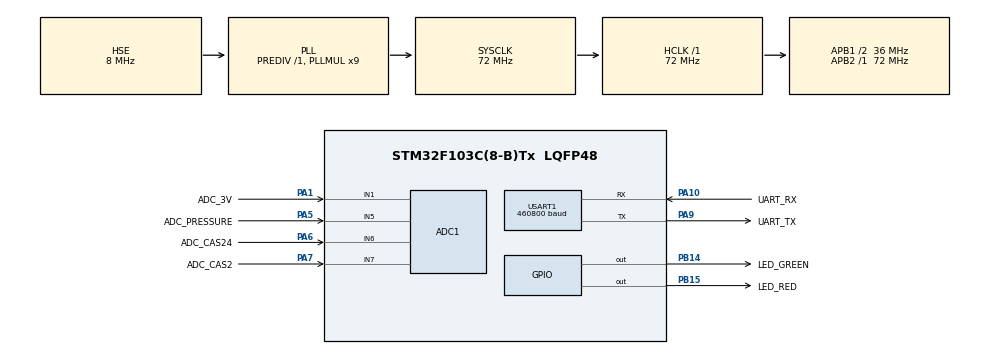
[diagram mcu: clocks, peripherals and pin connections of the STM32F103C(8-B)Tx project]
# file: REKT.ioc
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ADC1.Channel-10\#ChannelRegularConversion=ADC_CHANNEL_7
ADC1.Channel-8\#ChannelRegularConversion=ADC_CHANNEL_5
ADC1.Channel-9\#ChannelRegularConversion=ADC_CHANNEL_6
ADC1.ContinuousConvMode=ENABLE
ADC1.DataAlign=ADC_DATAALIGN_RIGHT
ADC1.DiscontinuousConvMode=DISABLE
ADC1.EnableAnalogWatchDog=false
ADC1.EnableRegularConversion=ENABLE
ADC1.ExternalTrigConv=ADC_SOFTWARE_START
ADC1.InjNumberOfConversion=0
ADC1.NbrOfConversion=3
ADC1.NbrOfConversionFlag=1
ADC1.Rank-10\#ChannelRegularConversion=3
ADC1.Rank-8\#ChannelRegularConversion=1
ADC1.Rank-9\#ChannelRegularConversion=2
ADC1.SamplingTime-10\#ChannelRegularConversion=ADC_SAMPLETIME_13CYCLES_5
ADC1.SamplingTime-8\#ChannelRegularConversion=ADC_SAMPLETIME_13CYCLES_5
ADC1.SamplingTime-9\#ChannelRegularConversion=ADC_SAMPLETIME_13CYCLES_5
ADC1.ScanConvMode=ADC_SCAN_ENABLE
ADC1.master=1
Dma.ADC1.0.Direction=DMA_PERIPH_TO_MEMORY
Dma.ADC1.0.Instance=DMA1_Channel1
Dma.ADC1.0.MemDataAlignment=DMA_MDATAALIGN_WORD
Dma.ADC1.0.MemInc=DMA_MINC_ENABLE
Dma.ADC1.0.Mode=DMA_CIRCULAR
Dma.ADC1.0.PeriphDataAlignment=DMA_PDATAALIGN_WORD
Dma.ADC1.0.PeriphInc=DMA_PINC_DISABLE
Dma.ADC1.0.Priority=DMA_PRIORITY_LOW
Dma.Request0=ADC1
Mcu.Family=STM32F1
Mcu.Name=STM32F103C(8-B)Tx
Mcu.Package=LQFP48
NVIC.DMA1_Channel1_IRQn=true\:0\:0\:true\:true\:true\:1\:false
NVIC.PriorityGroup=NVIC_PRIORITYGROUP_4
NVIC.TIM1_UP_IRQn=true\:0\:0\:false\:false\:true\:true
PA1.GPIO_Label=ADC_3V
PA1.Signal=ADCx_IN1
PA10.GPIO_Label=UART_RX
PA10.Mode=Asynchronous
PA10.Signal=USART1_RX
PA13.Mode=Serial_Wire
PA13.Signal=SYS_JTMS-SWDIO
PA14.Mode=Serial_Wire
PA14.Signal=SYS_JTCK-SWCLK
PA5.GPIO_Label=ADC_PRESSURE
PA5.Signal=ADCx_IN5
PA6.GPIO_Label=ADC_CAS24
PA6.Signal=ADCx_IN6
PA7.GPIO_Label=ADC_CAS2
PA7.Signal=ADCx_IN7
PA9.GPIO_Label=UART_TX
PA9.Mode=Asynchronous
PA9.Signal=USART1_TX
PB14.GPIO_Label=LED_GREEN
PB14.Signal=GPIO_Output
PB15.GPIO_Label=LED_RED
PB15.Signal=GPIO_Output
PD0-OSC_IN.Mode=HSE-External-Oscillator
PD0-OSC_IN.Signal=RCC_OSC_IN
PD1-OSC_OUT.Mode=HSE-External-Oscillator
PD1-OSC_OUT.Signal=RCC_OSC_OUT
ProjectManager.HeapSize=0x200
ProjectManager.StackSize=0x400
ProjectManager.TargetToolchain=Other Toolchains (GPDSC)
RCC.ADCPresc=RCC_ADCPCLK2_DIV6
RCC.AHBFreq_Value=72000000
RCC.APB1CLKDivider=RCC_HCLK_DIV2
RCC.APB1Freq_Value=36000000
RCC.APB1TimFreq_Value=72000000
RCC.APB2Freq_Value=72000000
RCC.APB2TimFreq_Value=72000000
RCC.HCLKFreq_Value=72000000
RCC.PLLMUL=RCC_PLL_MUL9
RCC.PLLSourceVirtual=RCC_PLLSOURCE_HSE
RCC.SYSCLKFreq_VALUE=72000000
RCC.SYSCLKSource=RCC_SYSCLKSOURCE_PLLCLK
RCC.USBFreq_Value=72000000
SH.ADCx_IN1.0=ADC1_IN1,IN1
SH.ADCx_IN5.0=ADC1_IN5,IN5
SH.ADCx_IN6.0=ADC1_IN6,IN6
SH.ADCx_IN7.0=ADC1_IN7,IN7
TIM1.Period=99
TIM1.Prescaler=71
USART1.BaudRate=460800
USART1.Mode=MODE_TX
USART1.VirtualMode=VM_ASYNC
VP_ADC1_Vref_Input.Mode=IN-Vrefint
VP_TIM1_VS_ClockSourceINT.Mode=Internal
board=REKT

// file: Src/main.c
/**
  ******************************************************************************
  * @file           : main.c
  * @brief          : Main program body
  ******************************************************************************
  ** This notice applies to any and all portions of this file
  * that are not between comment pairs USER CODE BEGIN and
  * USER CODE END. Other portions of this file, whether
  * inserted by the user or by software development tools
  * are owned by their respective copyright owners.
  *
  * COPYRIGHT(c) 2018 STMicroelectronics
  *
  * Redistribution and use in source and binary forms, with or without modification,
  * are permitted provided that the following conditions are met:
  *   1. Redistributions of source code must retain the above copyright notice,
  *      this list of conditions and the following disclaimer.
  *   2. Redistributions in binary form must reproduce the above copyright notice,
  *      this list of conditions and the following disclaimer in the documentation
  *      and/or other materials provided with the distribution.
  *   3. Neither the name of STMicroelectronics nor the names of its contributors
  *      may be used to endorse or promote products derived from this software
  *      without specific prior written permission.
  *
  * THIS SOFTWARE IS PROVIDED BY THE COPYRIGHT HOLDERS AND CONTRIBUTORS "AS IS"
  * AND ANY EXPRESS OR IMPLIED WARRANTIES, INCLUDING, BUT NOT LIMITED TO, THE
  * IMPLIED WARRANTIES OF MERCHANTABILITY AND FITNESS FOR A PARTICULAR PURPOSE ARE
  * DISCLAIMED. IN NO EVENT SHALL THE COPYRIGHT HOLDER OR CONTRIBUTORS BE LIABLE
  * FOR ANY DIRECT, INDIRECT, INCIDENTAL, SPECIAL, EXEMPLARY, OR CONSEQUENTIAL
  * DAMAGES (INCLUDING, BUT NOT LIMITED TO, PROCUREMENT OF SUBSTITUTE GOODS OR
  * SERVICES; LOSS OF USE, DATA, OR PROFITS; OR BUSINESS INTERRUPTION) HOWEVER
  * CAUSED AND ON ANY THEORY OF LIABILITY, WHETHER IN CONTRACT, STRICT LIABILITY,
  * OR TORT (INCLUDING NEGLIGENCE OR OTHERWISE) ARISING IN ANY WAY OUT OF THE USE
  * OF THIS SOFTWARE, EVEN IF ADVISED OF THE POSSIBILITY OF SUCH DAMAGE.
  *
  ******************************************************************************
  */
#include "main.h"
#include "stm32f1xx_hal.h"

/* USER CODE BEGIN Includes */
#include "rekt.h"
/* USER CODE END Includes */

ADC_HandleTypeDef hadc1;
DMA_HandleTypeDef hdma_adc1;

TIM_HandleTypeDef htim1;

UART_HandleTypeDef huart1;

void SystemClock_Config(void);
static void MX_GPIO_Init(void);
static void MX_DMA_Init(void);
static void MX_USART1_UART_Init(void);
static void MX_ADC1_Init(void);
static void MX_TIM1_Init(void);
static void MX_NVIC_Init(void);

int main(void)
{
  /* USER CODE BEGIN 1 */
#if DEBUG
  HAL_DBGMCU_EnableDBGSleepMode();
  HAL_DBGMCU_EnableDBGStopMode();
  HAL_DBGMCU_EnableDBGStandbyMode();
#endif
  /* USER CODE END 1 */

  /* MCU Configuration----------------------------------------------------------*/

  /* Reset of all peripherals, Initializes the Flash interface and the Systick. */
  HAL_Init();

  /* Configure the system clock */
  SystemClock_Config();

  /* Initialize all configured peripherals */
  MX_GPIO_Init();
  MX_DMA_Init();
  MX_USART1_UART_Init();
  MX_ADC1_Init();
  MX_TIM1_Init();

  /* Initialize interrupts */
  MX_NVIC_Init();
  /* USER CODE BEGIN 2 */
  rekt_init();
  rekt_loop();
  /* USER CODE END 2 */

  /* Infinite loop */
  while (1)
  {

  }

}

void SystemClock_Config(void)
{

  RCC_OscInitTypeDef RCC_OscInitStruct;
  RCC_ClkInitTypeDef RCC_ClkInitStruct;
  RCC_PeriphCLKInitTypeDef PeriphClkInit;

    /**Initializes the CPU, AHB and APB busses clocks
    */
  RCC_OscInitStruct.OscillatorType = RCC_OSCILLATORTYPE_HSE;
  RCC_OscInitStruct.HSEState = RCC_HSE_ON;
  RCC_OscInitStruct.HSEPredivValue = RCC_HSE_PREDIV_DIV1;
  RCC_OscInitStruct.HSIState = RCC_HSI_ON;
  RCC_OscInitStruct.PLL.PLLState = RCC_PLL_ON;
  RCC_OscInitStruct.PLL.PLLSource = RCC_PLLSOURCE_HSE;
  RCC_OscInitStruct.PLL.PLLMUL = RCC_PLL_MUL9;
  if (HAL_RCC_OscConfig(&RCC_OscInitStruct) != HAL_OK)
  {
    _Error_Handler(__FILE__, __LINE__);
  }

    /**Initializes the CPU, AHB and APB busses clocks
    */
  RCC_ClkInitStruct.ClockType = RCC_CLOCKTYPE_HCLK|RCC_CLOCKTYPE_SYSCLK
                              |RCC_CLOCKTYPE_PCLK1|RCC_CLOCKTYPE_PCLK2;
  RCC_ClkInitStruct.SYSCLKSource = RCC_SYSCLKSOURCE_PLLCLK;
  RCC_ClkInitStruct.AHBCLKDivider = RCC_SYSCLK_DIV1;
  RCC_ClkInitStruct.APB1CLKDivider = RCC_HCLK_DIV2;
  RCC_ClkInitStruct.APB2CLKDivider = RCC_HCLK_DIV1;

  if (HAL_RCC_ClockConfig(&RCC_ClkInitStruct, FLASH_LATENCY_2) != HAL_OK)
  {
    _Error_Handler(__FILE__, __LINE__);
  }

  PeriphClkInit.PeriphClockSelection = RCC_PERIPHCLK_ADC;
  PeriphClkInit.AdcClockSelection = RCC_ADCPCLK2_DIV6;
  if (HAL_RCCEx_PeriphCLKConfig(&PeriphClkInit) != HAL_OK)
  {
    _Error_Handler(__FILE__, __LINE__);
  }

    /**Configure the Systick interrupt time
    */
  HAL_SYSTICK_Config(HAL_RCC_GetHCLKFreq()/1000);

    /**Configure the Systick
    */
  HAL_SYSTICK_CLKSourceConfig(SYSTICK_CLKSOURCE_HCLK);

  /* SysTick_IRQn interrupt configuration */
  HAL_NVIC_SetPriority(SysTick_IRQn, 0, 0);
}

/**
  * @brief NVIC Configuration.
  * @retval None
  */
static void MX_NVIC_Init(void)
{
  /* DMA1_Channel1_IRQn interrupt configuration */
  HAL_NVIC_SetPriority(DMA1_Channel1_IRQn, 0, 0);
  HAL_NVIC_EnableIRQ(DMA1_Channel1_IRQn);
}

/* ADC1 init function */
static void MX_ADC1_Init(void)
{

  ADC_ChannelConfTypeDef sConfig;

    /**Common config
    */
  hadc1.Instance = ADC1;
  hadc1.Init.ScanConvMode = ADC_SCAN_ENABLE;
  hadc1.Init.ContinuousConvMode = ENABLE;
  hadc1.Init.DiscontinuousConvMode = DISABLE;
  hadc1.Init.ExternalTrigConv = ADC_SOFTWARE_START;
  hadc1.Init.DataAlign = ADC_DATAALIGN_RIGHT;
  hadc1.Init.NbrOfConversion = 3;
  if (HAL_ADC_Init(&hadc1) != HAL_OK)
  {
    _Error_Handler(__FILE__, __LINE__);
  }

    /**Configure Regular Channel
    */
  sConfig.Channel = ADC_CHANNEL_5;
  sConfig.Rank = ADC_REGULAR_RANK_1;
  sConfig.SamplingTime = ADC_SAMPLETIME_13CYCLES_5;
  if (HAL_ADC_ConfigChannel(&hadc1, &sConfig) != HAL_OK)
  {
    _Error_Handler(__FILE__, __LINE__);
  }

    /**Configure Regular Channel
    */
  sConfig.Channel = ADC_CHANNEL_6;
  sConfig.Rank = ADC_REGULAR_RANK_2;
  if (HAL_ADC_ConfigChannel(&hadc1, &sConfig) != HAL_OK)
  {
    _Error_Handler(__FILE__, __LINE__);
  }

    /**Configure Regular Channel
    */
  sConfig.Channel = ADC_CHANNEL_7;
  sConfig.Rank = ADC_REGULAR_RANK_3;
  if (HAL_ADC_ConfigChannel(&hadc1, &sConfig) != HAL_OK)
  {
    _Error_Handler(__FILE__, __LINE__);
  }

}

/* TIM1 init function */
static void MX_TIM1_Init(void)
{

  TIM_ClockConfigTypeDef sClockSourceConfig;
  TIM_MasterConfigTypeDef sMasterConfig;

  htim1.Instance = TIM1;
  htim1.Init.Prescaler = 71;
  htim1.Init.CounterMode = TIM_COUNTERMODE_UP;
  htim1.Init.Period = 99;
  htim1.Init.ClockDivision = TIM_CLOCKDIVISION_DIV1;
  htim1.Init.RepetitionCounter = 0;
  htim1.Init.AutoReloadPreload = TIM_AUTORELOAD_PRELOAD_DISABLE;
  if (HAL_TIM_Base_Init(&htim1) != HAL_OK)
  {
    _Error_Handler(__FILE__, __LINE__);
  }

  sClockSourceConfig.ClockSource = TIM_CLOCKSOURCE_INTERNAL;
  if (HAL_TIM_ConfigClockSource(&htim1, &sClockSourceConfig) != HAL_OK)
  {
    _Error_Handler(__FILE__, __LINE__);
  }

  sMasterConfig.MasterOutputTrigger = TIM_TRGO_RESET;
  sMasterConfig.MasterSlaveMode = TIM_MASTERSLAVEMODE_DISABLE;
  if (HAL_TIMEx_MasterConfigSynchronization(&htim1, &sMasterConfig) != HAL_OK)
  {
    _Error_Handler(__FILE__, __LINE__);
  }

}

/* USART1 init function */
static void MX_USART1_UART_Init(void)
{

  huart1.Instance = USART1;
  huart1.Init.BaudRate = 460800;
  huart1.Init.WordLength = UART_WORDLENGTH_8B;
  huart1.Init.StopBits = UART_STOPBITS_1;
  huart1.Init.Parity = UART_PARITY_NONE;
  huart1.Init.Mode = UART_MODE_TX;
  huart1.Init.HwFlowCtl = UART_HWCONTROL_NONE;
  huart1.Init.OverSampling = UART_OVERSAMPLING_16;
  if (HAL_UART_Init(&huart1) != HAL_OK)
  {
    _Error_Handler(__FILE__, __LINE__);
  }

}

static void MX_DMA_Init(void)
{
  /* DMA controller clock enable */
  __HAL_RCC_DMA1_CLK_ENABLE();

}

/** Configure pins as
        * Analog
        * Input
        * Output
        * EVENT_OUT
        * EXTI
*/
static void MX_GPIO_Init(void)
{

  GPIO_InitTypeDef GPIO_InitStruct;

  /* GPIO Ports Clock Enable */
  __HAL_RCC_GPIOD_CLK_ENABLE();
  __HAL_RCC_GPIOA_CLK_ENABLE();
  __HAL_RCC_GPIOB_CLK_ENABLE();

  /*Configure GPIO pin Output Level */
  HAL_GPIO_WritePin(GPIOB, LED_GREEN_Pin|LED_RED_Pin, GPIO_PIN_RESET);

  /*Configure GPIO pins : LED_GREEN_Pin LED_RED_Pin */
  GPIO_InitStruct.Pin = LED_GREEN_Pin|LED_RED_Pin;
  GPIO_InitStruct.Mode = GPIO_MODE_OUTPUT_PP;
  GPIO_InitStruct.Pull = GPIO_NOPULL;
  GPIO_InitStruct.Speed = GPIO_SPEED_FREQ_LOW;
  HAL_GPIO_Init(GPIOB, &GPIO_InitStruct);

}

void _Error_Handler(char *file, int line)
{
  /* USER CODE BEGIN Error_Handler_Debug */
  rekt_fault();
  /* USER CODE END Error_Handler_Debug */
}

/************************ (C) COPYRIGHT STMicroelectronics *****END OF FILE****/
